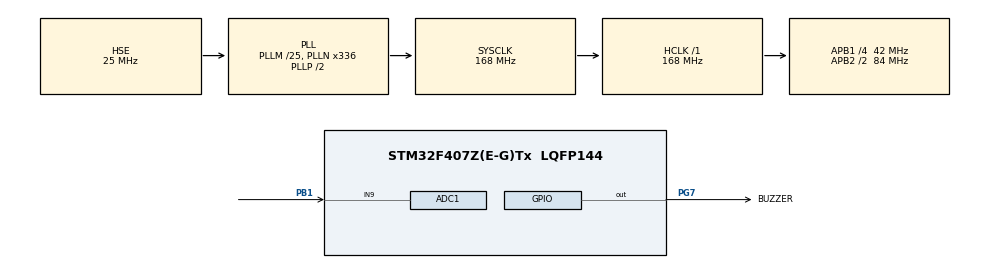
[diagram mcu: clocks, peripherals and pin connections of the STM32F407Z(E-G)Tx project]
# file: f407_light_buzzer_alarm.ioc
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ADC1.Channel-0\#ChannelRegularConversion=ADC_CHANNEL_9
ADC1.NbrOfConversionFlag=1
ADC1.Rank-0\#ChannelRegularConversion=1
ADC1.SamplingTime-0\#ChannelRegularConversion=ADC_SAMPLETIME_84CYCLES
ADC1.master=1
Mcu.Family=STM32F4
Mcu.Name=STM32F407Z(E-G)Tx
Mcu.Package=LQFP144
NVIC.PriorityGroup=NVIC_PRIORITYGROUP_4
PA13.Mode=Serial_Wire
PA13.Signal=SYS_JTMS-SWDIO
PA14.Mode=Serial_Wire
PA14.Signal=SYS_JTCK-SWCLK
PB1.Signal=ADCx_IN9
PG7.GPIO_Label=BUZZER
PG7.Signal=GPIO_Output
PH0-OSC_IN.Mode=HSE-External-Oscillator
PH0-OSC_IN.Signal=RCC_OSC_IN
PH1-OSC_OUT.Mode=HSE-External-Oscillator
PH1-OSC_OUT.Signal=RCC_OSC_OUT
ProjectManager.HeapSize=0x200
ProjectManager.StackSize=0x400
ProjectManager.TargetToolchain=CMake
RCC.48MHZClocksFreq_Value=84000000
RCC.AHBFreq_Value=168000000
RCC.APB1CLKDivider=RCC_HCLK_DIV4
RCC.APB1Freq_Value=42000000
RCC.APB1TimFreq_Value=84000000
RCC.APB2CLKDivider=RCC_HCLK_DIV2
RCC.APB2Freq_Value=84000000
RCC.APB2TimFreq_Value=168000000
RCC.CortexFreq_Value=168000000
RCC.HCLKFreq_Value=168000000
RCC.HSE_VALUE=25000000
RCC.HSI_VALUE=16000000
RCC.LSE_VALUE=32768
RCC.PLLM=25
RCC.PLLN=336
RCC.PLLSourceVirtual=RCC_PLLSOURCE_HSE
RCC.SYSCLKFreq_VALUE=168000000
RCC.SYSCLKSource=RCC_SYSCLKSOURCE_PLLCLK
RCC.VCOOutputFreq_Value=336000000
SH.ADCx_IN9.0=ADC1_IN9,IN9
board=custom

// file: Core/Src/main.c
/* USER CODE BEGIN Header */
/**
  ******************************************************************************
  * @file           : main.c
  * @brief          : Main program body
  ******************************************************************************
  * @attention
  *
  * Copyright (c) 2026 STMicroelectronics.
  * All rights reserved.
  *
  * This software is licensed under terms that can be found in the LICENSE file
  * in the root directory of this software component.
  * If no LICENSE file comes with this software, it is provided AS-IS.
  *
  ******************************************************************************
  */
/* USER CODE END Header */
#include "main.h"

/* USER CODE BEGIN PD */
/* USER CODE BEGIN PD */

/* 正常光照和遮挡状态之间需要下降的ADC差值 */
#define LIGHT_ALARM_DROP       500U

/* 恢复报警时使用较小阈值，构成滞回，避免临界点反复响停 */
#define LIGHT_CLEAR_DROP       250U

/* 每次读取进行多次采样取平均，减少ADC波动 */
#define LIGHT_SAMPLE_COUNT     16U

/* USER CODE END PD */
/* USER CODE END PD */

ADC_HandleTypeDef hadc1;

/* USER CODE BEGIN PV */
/* USER CODE BEGIN PV */

/* 启动时记录的正常环境光ADC值 */
static volatile uint32_t light_baseline = 0U;

/* 当前ADC平均值，可在调试器Watch窗口观察 */
static volatile uint32_t light_adc = 0U;

/* 当前报警状态：0不报警，1报警 */
static uint8_t alarm_on = 0U;

/* USER CODE END PV */
/* USER CODE END PV */

void SystemClock_Config(void);
static void MX_GPIO_Init(void);
static void MX_ADC1_Init(void);
/* USER CODE BEGIN PFP */
/* USER CODE BEGIN PFP */

static uint32_t ADC_ReadAverage(uint32_t samples);
static void Buzzer_Set(uint8_t on);

/* USER CODE END PFP */
/* USER CODE END PFP */

int main(void)
{

  /* MCU Configuration--------------------------------------------------------*/

  /* Reset of all peripherals, Initializes the Flash interface and the Systick. */
  HAL_Init();

  /* Configure the system clock */
  SystemClock_Config();

  /* Initialize all configured peripherals */
  MX_GPIO_Init();
  MX_ADC1_Init();
  /* USER CODE BEGIN 2 */
  /* USER CODE BEGIN 2 */

/* 启动时确保蜂鸣器关闭 */
Buzzer_Set(0U);

/*
 * 留出2秒时间。
 * 在这2秒内不要遮挡光敏电阻，
 * 程序会把当前光照作为正常环境基准。
 */
HAL_Delay(2000U);

/* 读取64次并取平均，得到正常光照基准 */
light_baseline = ADC_ReadAverage(64U);

/* USER CODE END 2 */
  /* USER CODE END 2 */

  /* Infinite loop */
while (1)
{

  /* USER CODE BEGIN 3 */

  /* 获取当前光照ADC平均值 */
  light_adc = ADC_ReadAverage(LIGHT_SAMPLE_COUNT);

  /*
   * 按照指定接线，遮挡后ADC值下降。
   * 当前值比基准值低500以上时，启动报警。
   */
  if ((alarm_on == 0U) &&
      ((light_adc + LIGHT_ALARM_DROP) < light_baseline))
  {
    alarm_on = 1U;
    Buzzer_Set(1U);
  }

  /*
   * 光照恢复后关闭报警。
   * 开启和关闭阈值不同，形成滞回，
   * 防止蜂鸣器在临界亮度下反复响停。
   */
  if ((alarm_on != 0U) &&
      ((light_adc + LIGHT_CLEAR_DROP) >= light_baseline))
  {
    alarm_on = 0U;
    Buzzer_Set(0U);
  }

  /* 每50ms检测一次，已经足够灵敏 */
  HAL_Delay(50U);

  /* USER CODE END 3 */
}
}

void SystemClock_Config(void)
{
  RCC_OscInitTypeDef RCC_OscInitStruct = {0};
  RCC_ClkInitTypeDef RCC_ClkInitStruct = {0};

  /** Configure the main internal regulator output voltage
  */
  __HAL_RCC_PWR_CLK_ENABLE();
  __HAL_PWR_VOLTAGESCALING_CONFIG(PWR_REGULATOR_VOLTAGE_SCALE1);

  /** Initializes the RCC Oscillators according to the specified parameters
  * in the RCC_OscInitTypeDef structure.
  */
  RCC_OscInitStruct.OscillatorType = RCC_OSCILLATORTYPE_HSE;
  RCC_OscInitStruct.HSEState = RCC_HSE_ON;
  RCC_OscInitStruct.PLL.PLLState = RCC_PLL_ON;
  RCC_OscInitStruct.PLL.PLLSource = RCC_PLLSOURCE_HSE;
  RCC_OscInitStruct.PLL.PLLM = 25;
  RCC_OscInitStruct.PLL.PLLN = 336;
  RCC_OscInitStruct.PLL.PLLP = RCC_PLLP_DIV2;
  RCC_OscInitStruct.PLL.PLLQ = 4;
  if (HAL_RCC_OscConfig(&RCC_OscInitStruct) != HAL_OK)
  {
    Error_Handler();
  }

  /** Initializes the CPU, AHB and APB buses clocks
  */
  RCC_ClkInitStruct.ClockType = RCC_CLOCKTYPE_HCLK|RCC_CLOCKTYPE_SYSCLK
                              |RCC_CLOCKTYPE_PCLK1|RCC_CLOCKTYPE_PCLK2;
  RCC_ClkInitStruct.SYSCLKSource = RCC_SYSCLKSOURCE_PLLCLK;
  RCC_ClkInitStruct.AHBCLKDivider = RCC_SYSCLK_DIV1;
  RCC_ClkInitStruct.APB1CLKDivider = RCC_HCLK_DIV4;
  RCC_ClkInitStruct.APB2CLKDivider = RCC_HCLK_DIV2;

  if (HAL_RCC_ClockConfig(&RCC_ClkInitStruct, FLASH_LATENCY_5) != HAL_OK)
  {
    Error_Handler();
  }
}

static void MX_ADC1_Init(void)
{

  ADC_ChannelConfTypeDef sConfig = {0};

  /** Configure the global features of the ADC (Clock, Resolution, Data Alignment and number of conversion)
  */
  hadc1.Instance = ADC1;
  hadc1.Init.ClockPrescaler = ADC_CLOCK_SYNC_PCLK_DIV4;
  hadc1.Init.Resolution = ADC_RESOLUTION_12B;
  hadc1.Init.ScanConvMode = DISABLE;
  hadc1.Init.ContinuousConvMode = DISABLE;
  hadc1.Init.DiscontinuousConvMode = DISABLE;
  hadc1.Init.ExternalTrigConvEdge = ADC_EXTERNALTRIGCONVEDGE_NONE;
  hadc1.Init.ExternalTrigConv = ADC_SOFTWARE_START;
  hadc1.Init.DataAlign = ADC_DATAALIGN_RIGHT;
  hadc1.Init.NbrOfConversion = 1;
  hadc1.Init.DMAContinuousRequests = DISABLE;
  hadc1.Init.EOCSelection = ADC_EOC_SINGLE_CONV;
  if (HAL_ADC_Init(&hadc1) != HAL_OK)
  {
    Error_Handler();
  }

  /** Configure for the selected ADC regular channel its corresponding rank in the sequencer and its sample time.
  */
  sConfig.Channel = ADC_CHANNEL_9;
  sConfig.Rank = 1;
  sConfig.SamplingTime = ADC_SAMPLETIME_84CYCLES;
  if (HAL_ADC_ConfigChannel(&hadc1, &sConfig) != HAL_OK)
  {
    Error_Handler();
  }

}

static void MX_GPIO_Init(void)
{
  GPIO_InitTypeDef GPIO_InitStruct = {0};

  /* GPIO Ports Clock Enable */
  __HAL_RCC_GPIOH_CLK_ENABLE();
  __HAL_RCC_GPIOB_CLK_ENABLE();
  __HAL_RCC_GPIOG_CLK_ENABLE();
  __HAL_RCC_GPIOA_CLK_ENABLE();

  /*Configure GPIO pin Output Level */
  HAL_GPIO_WritePin(BUZZER_GPIO_Port, BUZZER_Pin, GPIO_PIN_RESET);

  /*Configure GPIO pin : BUZZER_Pin */
  GPIO_InitStruct.Pin = BUZZER_Pin;
  GPIO_InitStruct.Mode = GPIO_MODE_OUTPUT_PP;
  GPIO_InitStruct.Pull = GPIO_NOPULL;
  GPIO_InitStruct.Speed = GPIO_SPEED_FREQ_LOW;
  HAL_GPIO_Init(BUZZER_GPIO_Port, &GPIO_InitStruct);

}

/* USER CODE BEGIN 4 */
/* USER CODE BEGIN 4 */

/**
 * @brief  多次读取ADC并计算平均值
 * @param  samples 采样次数，必须大于0
 * @retval ADC平均值，12位ADC范围为0～4095
 */
static uint32_t ADC_ReadAverage(uint32_t samples)
{
  uint32_t sum = 0U;
  uint32_t i;

  if (samples == 0U)
  {
    return 0U;
  }

  for (i = 0U; i < samples; i++)
  {
    /* 启动一次ADC转换 */
    if (HAL_ADC_Start(&hadc1) != HAL_OK)
    {
      Error_Handler();
    }

    /* 最多等待10ms，直到转换完成 */
    if (HAL_ADC_PollForConversion(&hadc1, 10U) != HAL_OK)
    {
      Error_Handler();
    }

    /* 读取ADC1数据寄存器中的转换结果 */
    sum += HAL_ADC_GetValue(&hadc1);

    /* 停止本次转换 */
    if (HAL_ADC_Stop(&hadc1) != HAL_OK)
    {
      Error_Handler();
    }
  }

  return sum / samples;
}

/**
 * @brief 控制板载蜂鸣器
 * @param on 1：响；0：关闭
 */
static void Buzzer_Set(uint8_t on)
{
  /*
   * 霸天虎板载蜂鸣器PG7高电平有效：
   * GPIO_PIN_SET   = 蜂鸣器响
   * GPIO_PIN_RESET = 蜂鸣器关闭
   */
  HAL_GPIO_WritePin(
      BUZZER_GPIO_Port,
      BUZZER_Pin,
      (on != 0U) ? GPIO_PIN_SET : GPIO_PIN_RESET);
}

/* USER CODE END 4 */
/* USER CODE END 4 */

void Error_Handler(void)
{
  __disable_irq();
  while (1)
  {
  }
}
